# nrf9230_engb_celldsp register map
Vendor: Nordic Semiconductor; Series: nRF92; File version: 1
Registers are 32-bit, read-write, reset 0x0 unless marked. A register's access mark holds for its fields unless they carry their own. Offsets are from the block's base; [hi:lo] are bit positions; lines under a group give offsets from that group; {n}, {i} and the like mark numbered series; 'fields as' and 'values as' point back to an identical list.

## PCGCM0 — PCGC Master 0
Base 0x45015000
Same registers: PCGCM1 0x45023000
{0xE0+4i} SETPWRCONTHRESHOLDBASE[{i}] (i=0..2) — Description collection: Set power consumption threshold base for power source / regulator n
  [3:0] SETPWRCONTHRESHOLDBASE
0xC00 UNLOCKBACKDOORS
  [15:0] UNLOCKBACKDOORS — Write: 0x00009375 to lock/unlock backdoors Read: 0x00000001 if backdoors is enabled Read: 0x00000000 if backdoors is disabled
0xC04 ENABLEPOWERREGFORCE
  [2:0] ENABLEPOWERREGFORCE
0xC08 POWERREGFORCE — Force reg
  [2:0] POWERREGFORCEREG
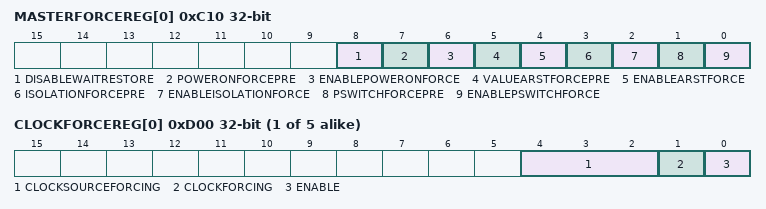
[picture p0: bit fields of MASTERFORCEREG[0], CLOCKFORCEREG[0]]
{0xC10+4i} MASTERFORCEREG[{i}] (i=0..0) — Description collection: Force reg
  [8] DISABLEWAITRESTORE — Turn off waiting for arst deactivation before retention restore
    1=Disable (Turn off waiting for arst deactivation before retention restore); 0=Enable (Wait for arst deactivation before retention restore)
  [7] POWERONFORCEPRE
  [6] ENABLEPOWERONFORCE
  [5] VALUEARSTFORCEPRE
  [4] ENABLEARSTFORCE
  [3] ISOLATIONFORCEPRE
  [2] ENABLEISOLATIONFORCE
  [1] PSWITCHFORCEPRE
  [0] ENABLEPSWITCHFORCE
{0xD00+4i} CLOCKFORCEREG[{i}] (i=0..4) — Description collection: Force clock n
  [4:2] CLOCKSOURCEFORCING
  [1] CLOCKFORCING
  [0] ENABLE — Enable clock forcing

## BILS — The Built-in Leakage Sensor (BILS) module.
Base 0x45018000
0x400 CONFIG group — Unspecified
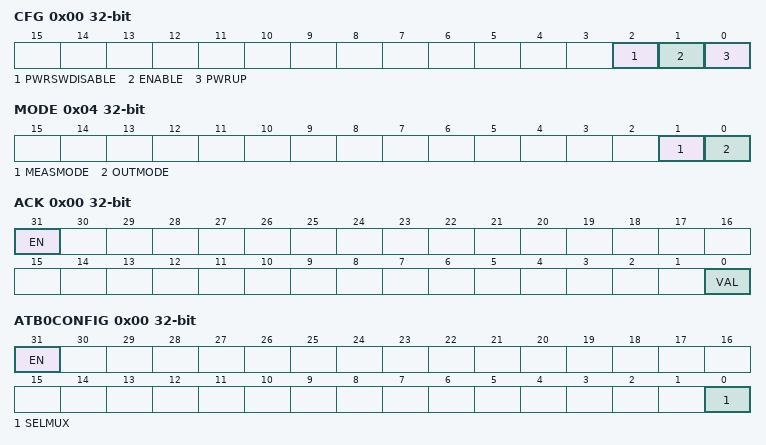
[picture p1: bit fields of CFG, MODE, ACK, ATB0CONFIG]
  0x00 CFG — BILS configuration
    [2] PWRSWDISABLE — Disable power switch.
      0=PwrSwNormalMode (Normal control of the power switch.); 1=PwrSwDisabledMode (Power switch is turned off.)
    [1] ENABLE — BILS enable
      0=BilsDisable (Disable BILS, REQ_SWOFF_AO_0V8 = 0); 1=BilsEnable (Enable BILS, REQ_SWOFF_AO_0V8 is controlled by BILS)
    [0] PWRUP — Power up BILS
      0=PwrOff (BILS is powered down and REQ_SWOFF_AO_0V8=0); 1=PwrOn (BILS is powered up)
  0x04 MODE — Mode selection
    [1] MEASMODE — Measurement mode selection
      0=MeasDisMode (Measure discharge rate); 1=MeasPwMode (Measure power switch chain propagation delay)
    [0] OUTMODE — Output mode selection
      0=Duty50Mode (50:50 duty cycle output selected to FOUT_AO_0V8 pin); 1=CompMode (Comparator output selected to FOUT_AO_0V8 pin)
0x500 OVERRIDE group — Unspecified
  0x00 ACK — Override the ACL_SWOFF_0V8 signal
    [31] EN — Override enable
      0=Disabled (Override disabled); 1=Enabled (Override is enabled)
    [0] VAL — Override value
0x600 DFT group — Unspecified
  0x00 ATB0CONFIG — Analog Test Bus 0 (ATB0) configuration
    [31] EN — Enable the analog test bus
      0=Disabled (Analog test bus is disabled); 1=Enabled (Analog test bus is enabled)
    [0] SELMUX — Select multiplexer for ATB0
      0=None selected; 1=Connect (Voltage on ATB0 used as threshold voltage)
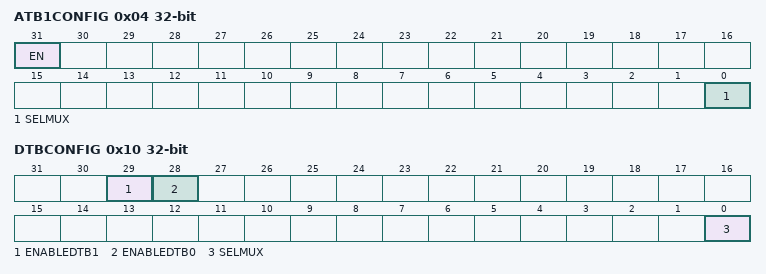
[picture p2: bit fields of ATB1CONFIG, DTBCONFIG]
  0x04 ATB1CONFIG — Analog Test Bus 1 (ATB1) configuration
    [31] EN — Enable the analog test bus
      values as DFT.ATB0CONFIG.EN
    [0] SELMUX — Select multiplexer for ATB1
      0=None selected; 1=ConnectDVDD (ATB1 connected to DVDD_0V8_SW)
  0x10 DTBCONFIG — Digital Test Bus configuration
    [29] ENABLEDTB1 — Enable the digital test bus
      0=Disabled (Digital test bus is disabled); 1=Enabled (Digital test bus is enabled)
    [28] ENABLEDTB0 — Enable the digital test bus
      values as ENABLEDTB1
    [0] SELMUX — Select multiplexer for DTB0
      0=None selected; 1=Connect (FOUT_AO_0V8 is connected to DTB0, REQ_SWOFF_AO_0V8 is connected to DTB1)

## DPPIC — Distributed programmable peripheral interconnect controller
Base 0x45021000
Same registers: GLOBAL_DPPIC120 0x5F8E1000, GLOBAL_DPPIC130 0x5F922000, GLOBAL_DPPIC131 0x5F981000, GLOBAL_DPPIC132 0x5F991000, GLOBAL_DPPIC133 0x5F9A1000, GLOBAL_DPPIC134 0x5F9B1000, GLOBAL_DPPIC135 0x5F9C1000, GLOBAL_DPPIC136 0x5F9D1000
{0x0+8i} TASKS_CHG[{i}] (i=0..3) group — Channel group tasks
  0x00 EN wo — Description cluster: Enable channel group n
    [0] EN — Enable channel group n
      1=Trigger task
  0x04 DIS wo — Description cluster: Disable channel group n
    [0] DIS — Disable channel group n
      1=Trigger task
{0x80+8i} SUBSCRIBE_CHG[{i}] (i=0..3) group — Subscribe configuration for tasks
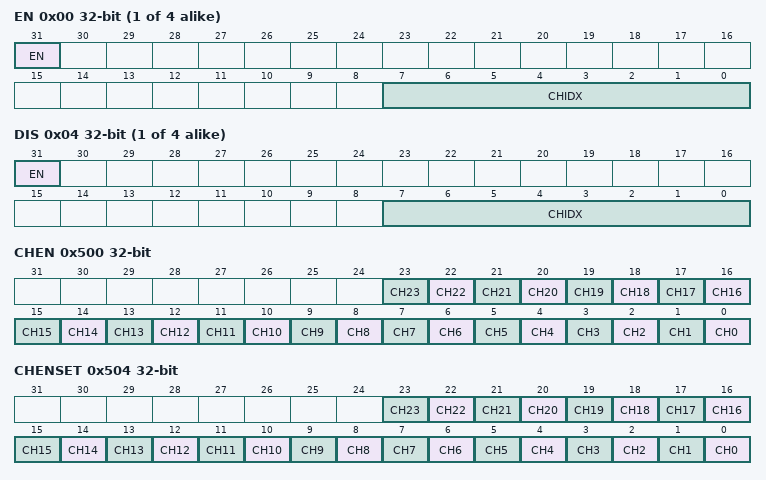
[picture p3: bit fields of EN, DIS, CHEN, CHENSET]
  0x00 EN — Description cluster: Subscribe configuration for task CHG[n].EN
    [31] EN
      0=Disabled (Disable subscription); 1=Enabled (Enable subscription)
    [7:0] CHIDX — DPPI channel that task CHG[n].EN will subscribe to
  0x04 DIS — Description cluster: Subscribe configuration for task CHG[n].DIS
    [31] EN
      values as SUBSCRIBE_CHG[0].EN.EN
    [7:0] CHIDX — DPPI channel that task CHG[n].DIS will subscribe to
0x500 CHEN — Channel enable register
  [all] fields
    0=Disabled (Disable channel); 1=Enabled (Enable channel)
  [n] CH{n} (n=0..23) — Enable or disable channel {n}
0x504 CHENSET write-1-sets — Channel enable set register
  [all] fields
    on read: 0=Disabled (Read: Channel disabled); 1=Enabled (Read: Channel enabled) | on write: 1=Set (Write: Enable channel)
  [n] CH{n} (n=0..23) — Channel {n} enable set register. Writing 0 has no effect.
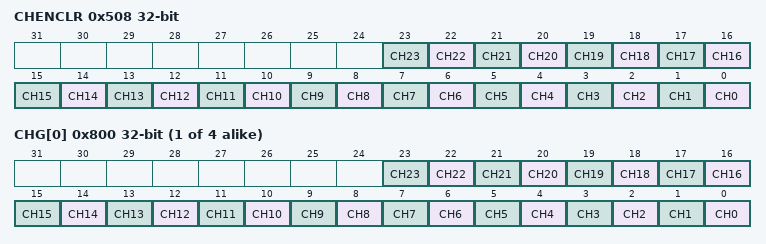
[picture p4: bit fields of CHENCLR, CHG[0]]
0x508 CHENCLR write-1-clears — Channel enable clear register
  [all] fields
    on read: 0=Disabled (Read: Channel disabled); 1=Enabled (Read: Channel enabled) | on write: 1=Clear (Write: Disable channel)
  [n] CH{n} (n=0..23) — Channel {n} enable clear register. Writing 0 has no effect.
{0x800+4i} CHG[{i}] (i=0..3) — Description collection: Channel group n Note: Writes to this register are ignored if either SUBSCRIBE_CHG[n].EN or SUBSCRIBE_CHG[n].DIS is enabled
  [all] fields
    0=Excluded; 1=Included
  [n] CH{n} (n=0..23) — Include or exclude channel {n}
